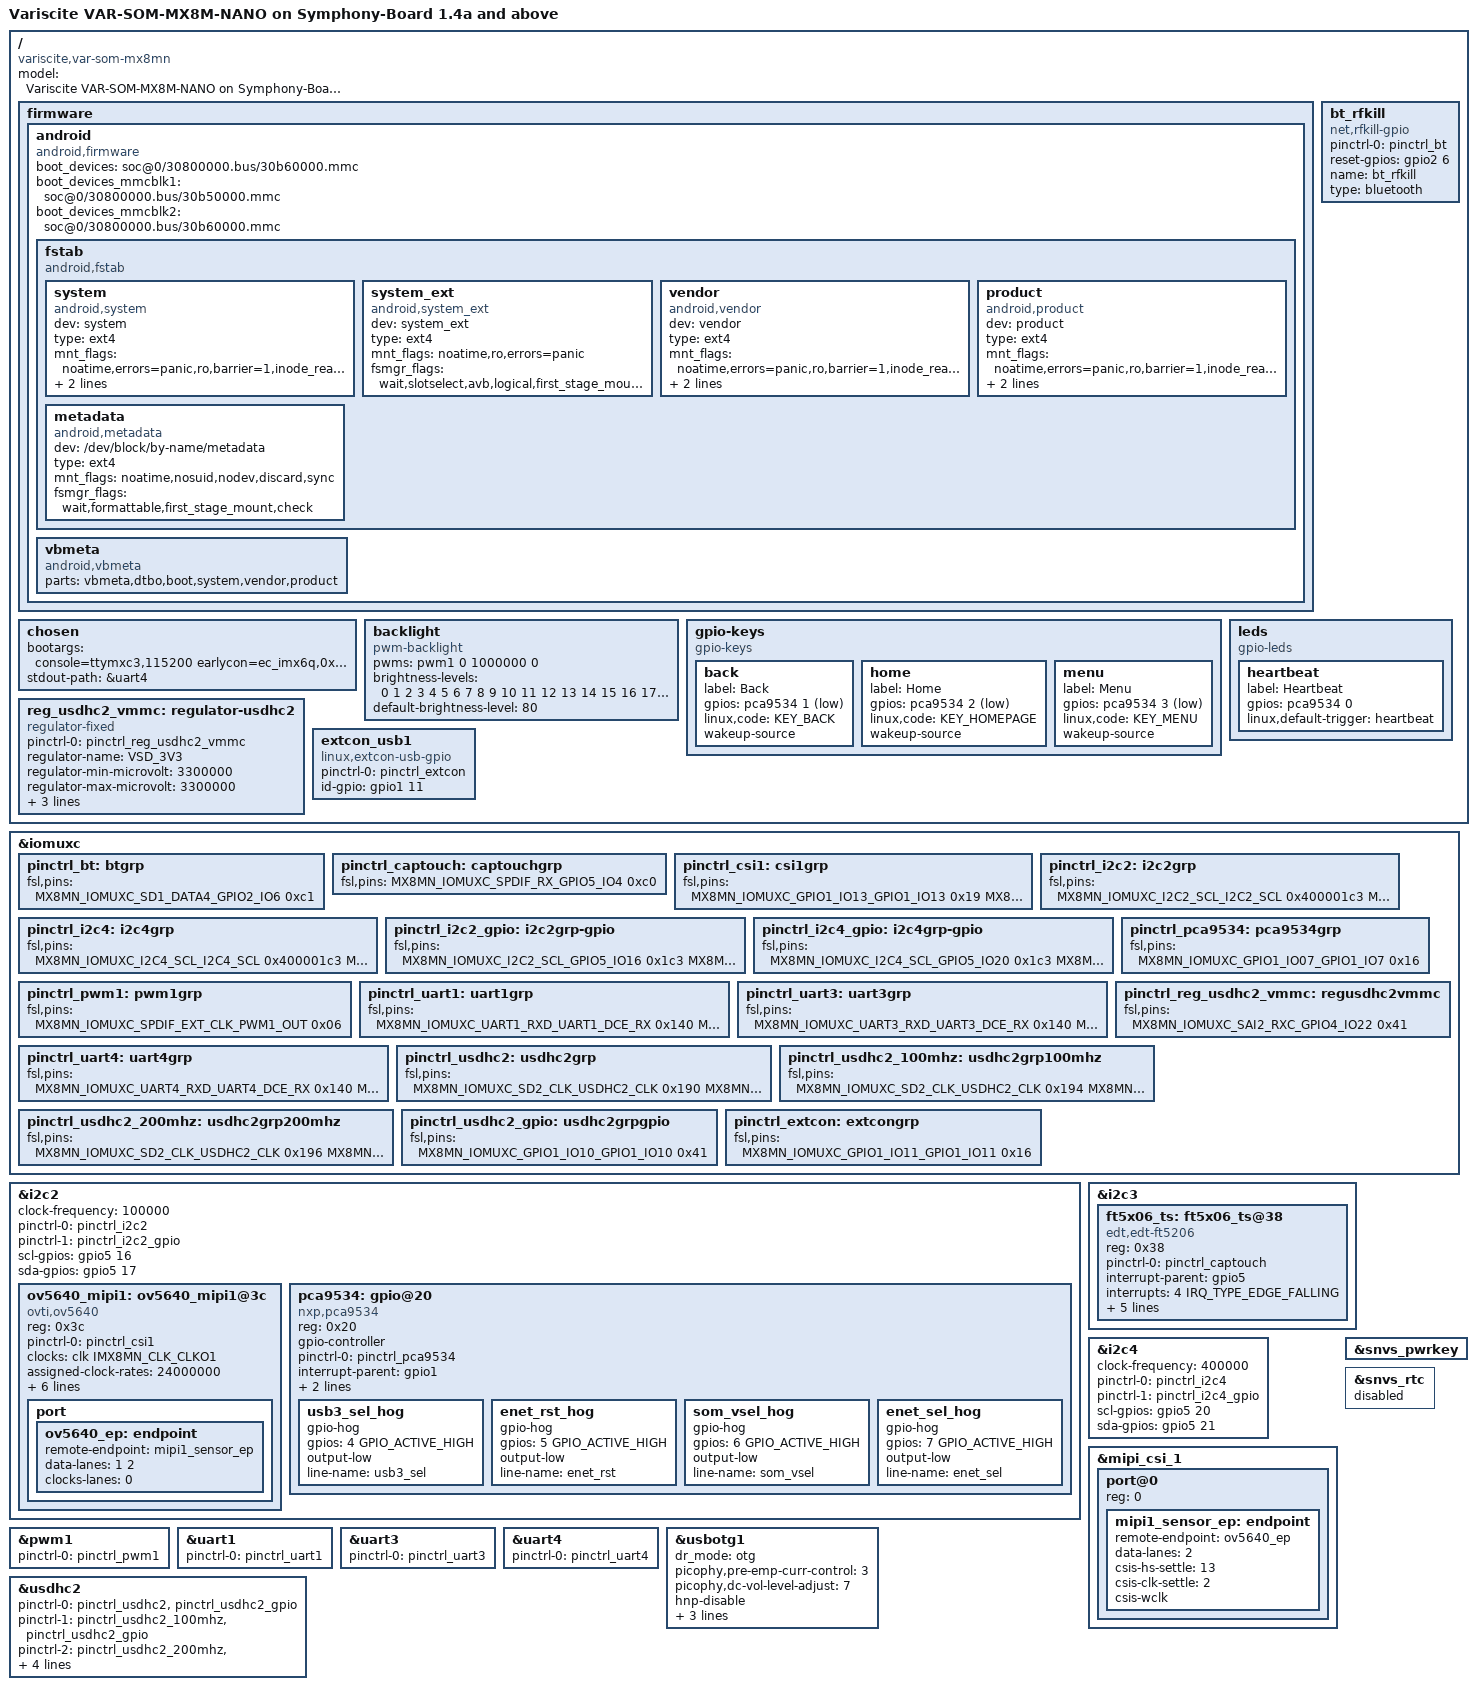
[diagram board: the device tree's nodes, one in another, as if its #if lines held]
// SPDX-License-Identifier: (GPL-2.0+ OR MIT)
/*
 * Copyright 2019 NXP
 * Copyright 2019-2020 Variscite Ltd.
 */

/dts-v1/;

#include <dt-bindings/usb/pd.h>
#include "imx8mn-var-som.dtsi"

/ {
	firmware {
		android {
			compatible = "android,firmware";
			/* default emmc node used for GSI */
			boot_devices = "soc@0/30800000.bus/30b60000.mmc";
			/* sd card node which used if androidboot.boot_device_root=mmcblk1 */
			boot_devices_mmcblk1 = "soc@0/30800000.bus/30b50000.mmc";
			/* emmc node which used if androidboot.boot_device_root=mmcblk2 */
			boot_devices_mmcblk2 = "soc@0/30800000.bus/30b60000.mmc";
			fstab {
				compatible = "android,fstab";
				system {
					compatible = "android,system";
					dev = "system";
					type = "ext4";
					mnt_flags = "noatime,errors=panic,ro,barrier=1,inode_readahead_blks=8";
					fsmgr_flags = "wait,slotselect,avb,avb_keys=/avb,logical,first_stage_mount";
				};
				system_ext {
					compatible = "android,system_ext";
					dev = "system_ext";
					type = "ext4";
					mnt_flags = "noatime,ro,errors=panic";
					fsmgr_flags = "wait,slotselect,avb,logical,first_stage_mount";
				};
				vendor {
					compatible = "android,vendor";
					dev = "vendor";
					type = "ext4";
					mnt_flags = "noatime,errors=panic,ro,barrier=1,inode_readahead_blks=8";
					fsmgr_flags = "wait,slotselect,avb,logical,first_stage_mount";
				};
				product {
					compatible = "android,product";
					dev = "product";
					type = "ext4";
					mnt_flags = "noatime,errors=panic,ro,barrier=1,inode_readahead_blks=8";
					fsmgr_flags = "wait,slotselect,avb,logical,first_stage_mount";
				};
				metadata {
					compatible = "android,metadata";
					dev = "/dev/block/by-name/metadata";
					type = "ext4";
					mnt_flags = "noatime,nosuid,nodev,discard,sync";
					fsmgr_flags = "wait,formattable,first_stage_mount,check";
				};
			};
			vbmeta {
				/*we need use FirstStageMountVBootV2 if we enable avb*/
				compatible = "android,vbmeta";
				/*parts means the partition witch can be mount in first stage*/
				parts = "vbmeta,dtbo,boot,system,vendor,product";
			};
		};
	};
};

/ {
	 bt_rfkill {
               compatible = "net,rfkill-gpio";
               pinctrl-names = "default";
               pinctrl-0 = <&pinctrl_bt>;
               reset-gpios = <&gpio2 6 GPIO_ACTIVE_HIGH>;
               name = "bt_rfkill";
               type = "bluetooth";
               status = "okay";
       };
};

/ {
	model = "Variscite VAR-SOM-MX8M-NANO on Symphony-Board 1.4a and above";
	compatible = "variscite,var-som-mx8mn", "fsl,imx8mn";

	chosen {
		bootargs = "console=ttymxc3,115200 earlycon=ec_imx6q,0x30a60000,115200 loglevel=8";
		stdout-path = &uart4;
	};

	backlight: backlight {
		compatible = "pwm-backlight";
		pwms = <&pwm1 0 1000000 0>;
		brightness-levels = < 0  1  2  3  4  5  6  7  8  9
				     10 11 12 13 14 15 16 17 18 19
				     20 21 22 23 24 25 26 27 28 29
				     30 31 32 33 34 35 36 37 38 39
				     40 41 42 43 44 45 46 47 48 49
				     50 51 52 53 54 55 56 57 58 59
				     60 61 62 63 64 65 66 67 68 69
				     70 71 72 73 74 75 76 77 78 79
				     80 81 82 83 84 85 86 87 88 89
				     90 91 92 93 94 95 96 97 98 99
				    100>;
		default-brightness-level = <80>;
		status = "okay";
	};

	gpio-keys {
		compatible = "gpio-keys";
		status = "okay";

		back {
			label = "Back";
			gpios = <&pca9534 1 GPIO_ACTIVE_LOW>;
			linux,code = <KEY_BACK>;
			wakeup-source;
		};

		home {
			label = "Home";
			gpios = <&pca9534 2 GPIO_ACTIVE_LOW>;
			linux,code = <KEY_HOMEPAGE>;
			wakeup-source;
		};

		menu {
			label = "Menu";
			gpios = <&pca9534 3 GPIO_ACTIVE_LOW>;
			linux,code = <KEY_MENU>;
			wakeup-source;
		};
	};

	leds {
		compatible = "gpio-leds";
		status = "okay";

		heartbeat {
			label = "Heartbeat";
			gpios = <&pca9534 0 GPIO_ACTIVE_HIGH>;
			linux,default-trigger = "heartbeat";
		};
	};

	reg_usdhc2_vmmc: regulator-usdhc2 {
		compatible = "regulator-fixed";
		pinctrl-names = "default";
		pinctrl-0 = <&pinctrl_reg_usdhc2_vmmc>;
		regulator-name = "VSD_3V3";
		regulator-min-microvolt = <3300000>;
		regulator-max-microvolt = <3300000>;
		gpio = <&gpio4 22 GPIO_ACTIVE_HIGH>;
		off-on-delay = <20000>;
		enable-active-high;
	};

	extcon_usb1: extcon_usb1 {
		compatible = "linux,extcon-usb-gpio";
		pinctrl-names = "default";
		pinctrl-0 = <&pinctrl_extcon>;
		id-gpio = <&gpio1 11 GPIO_ACTIVE_HIGH>;
		status = "okay";
	};
};

&iomuxc {

	pinctrl_bt: btgrp {
		fsl,pins = <
			MX8MN_IOMUXC_SD1_DATA4_GPIO2_IO6               0xc1 /* BT_REG_ON    */
		>;
        };

	pinctrl_captouch: captouchgrp {
		fsl,pins = <
			MX8MN_IOMUXC_SPDIF_RX_GPIO5_IO4			0xc0
		>;
	};

	pinctrl_csi1: csi1grp {
		fsl,pins = <
			MX8MN_IOMUXC_GPIO1_IO13_GPIO1_IO13		0x19
			MX8MN_IOMUXC_ECSPI2_MISO_GPIO5_IO12		0x19
		>;
	};

	pinctrl_i2c2: i2c2grp {
		fsl,pins = <
			MX8MN_IOMUXC_I2C2_SCL_I2C2_SCL			0x400001c3
			MX8MN_IOMUXC_I2C2_SDA_I2C2_SDA			0x400001c3
		>;
	};

	pinctrl_i2c4: i2c4grp {
		fsl,pins = <
			MX8MN_IOMUXC_I2C4_SCL_I2C4_SCL			0x400001c3
			MX8MN_IOMUXC_I2C4_SDA_I2C4_SDA			0x400001c3
		>;
	};

	pinctrl_i2c2_gpio: i2c2grp-gpio {
		fsl,pins = <
			MX8MN_IOMUXC_I2C2_SCL_GPIO5_IO16		0x1c3
			MX8MN_IOMUXC_I2C2_SDA_GPIO5_IO17		0x1c3
		>;
	};

	pinctrl_i2c4_gpio: i2c4grp-gpio {
		fsl,pins = <
			MX8MN_IOMUXC_I2C4_SCL_GPIO5_IO20		0x1c3
			MX8MN_IOMUXC_I2C4_SDA_GPIO5_IO21		0x1c3
		>;
	};

	pinctrl_pca9534: pca9534grp {
		fsl,pins = <
			MX8MN_IOMUXC_GPIO1_IO07_GPIO1_IO7		0x16
		>;
	};

	pinctrl_pwm1: pwm1grp {
		fsl,pins = <
			MX8MN_IOMUXC_SPDIF_EXT_CLK_PWM1_OUT		0x06
		>;
	};

	pinctrl_uart1: uart1grp {
		fsl,pins = <
			MX8MN_IOMUXC_UART1_RXD_UART1_DCE_RX		0x140
			MX8MN_IOMUXC_UART1_TXD_UART1_DCE_TX		0x140
		>;
	};

	pinctrl_uart3: uart3grp {
		fsl,pins = <
			MX8MN_IOMUXC_UART3_RXD_UART3_DCE_RX		0x140
			MX8MN_IOMUXC_UART3_TXD_UART3_DCE_TX		0x140
		>;
	};

	pinctrl_uart4: uart4grp {
		fsl,pins = <
			MX8MN_IOMUXC_UART4_RXD_UART4_DCE_RX		0x140
			MX8MN_IOMUXC_UART4_TXD_UART4_DCE_TX		0x140
		>;
	};

	pinctrl_reg_usdhc2_vmmc: regusdhc2vmmc {
		fsl,pins = <
			MX8MN_IOMUXC_SAI2_RXC_GPIO4_IO22		0x41
		>;
	};

	pinctrl_usdhc2: usdhc2grp {
		fsl,pins = <
			MX8MN_IOMUXC_SD2_CLK_USDHC2_CLK			0x190
			MX8MN_IOMUXC_SD2_CMD_USDHC2_CMD			0x1d0
			MX8MN_IOMUXC_SD2_DATA0_USDHC2_DATA0		0x1d0
			MX8MN_IOMUXC_SD2_DATA1_USDHC2_DATA1		0x1d0
			MX8MN_IOMUXC_SD2_DATA2_USDHC2_DATA2		0x1d0
			MX8MN_IOMUXC_SD2_DATA3_USDHC2_DATA3		0x1d0
			MX8MN_IOMUXC_GPIO1_IO04_USDHC2_VSELECT		0x1d0
		>;
	};

	pinctrl_usdhc2_100mhz: usdhc2grp100mhz {
		fsl,pins = <
			MX8MN_IOMUXC_SD2_CLK_USDHC2_CLK			0x194
			MX8MN_IOMUXC_SD2_CMD_USDHC2_CMD			0x1d4
			MX8MN_IOMUXC_SD2_DATA0_USDHC2_DATA0		0x1d4
			MX8MN_IOMUXC_SD2_DATA1_USDHC2_DATA1		0x1d4
			MX8MN_IOMUXC_SD2_DATA2_USDHC2_DATA2		0x1d4
			MX8MN_IOMUXC_SD2_DATA3_USDHC2_DATA3		0x1d4
			MX8MN_IOMUXC_GPIO1_IO04_USDHC2_VSELECT		0x1d0
		>;
	};

	pinctrl_usdhc2_200mhz: usdhc2grp200mhz {
		fsl,pins = <
			MX8MN_IOMUXC_SD2_CLK_USDHC2_CLK			0x196
			MX8MN_IOMUXC_SD2_CMD_USDHC2_CMD			0x1d6
			MX8MN_IOMUXC_SD2_DATA0_USDHC2_DATA0		0x1d6
			MX8MN_IOMUXC_SD2_DATA1_USDHC2_DATA1		0x1d6
			MX8MN_IOMUXC_SD2_DATA2_USDHC2_DATA2		0x1d6
			MX8MN_IOMUXC_SD2_DATA3_USDHC2_DATA3		0x1d6
			MX8MN_IOMUXC_GPIO1_IO04_USDHC2_VSELECT		0x1d0
		>;
	};

	pinctrl_usdhc2_gpio: usdhc2grpgpio {
		fsl,pins = <
			MX8MN_IOMUXC_GPIO1_IO10_GPIO1_IO10		0x41
		>;
	};

	pinctrl_extcon: extcongrp {
		fsl,pins = <
			MX8MN_IOMUXC_GPIO1_IO11_GPIO1_IO11		0x16
		>;
	};
};

&i2c2 {
	clock-frequency = <100000>;
	pinctrl-names = "default", "gpio";
	pinctrl-0 = <&pinctrl_i2c2>;
	pinctrl-1 = <&pinctrl_i2c2_gpio>;
	scl-gpios = <&gpio5 16 GPIO_ACTIVE_HIGH>;
	sda-gpios = <&gpio5 17 GPIO_ACTIVE_HIGH>;
	status = "okay";

	ov5640_mipi1: ov5640_mipi1@3c {
		status = "okay";
		compatible = "ovti,ov5640";
		reg = <0x3c>;
		pinctrl-names = "default";
		pinctrl-0 = <&pinctrl_csi1>;
		clocks = <&clk IMX8MN_CLK_CLKO1>;
		clock-names = "xclk";
/* Disabled CLKO1, since VAR-SOM-MX8M-NANO camera expansion board uses
 * its own oscillator. Enable CLK01 if your design requires it
 */
#if 0
		assigned-clocks = <&clk IMX8MN_CLK_CLKO1>;
		assigned-clock-parents = <&clk IMX8MN_CLK_24M>;
#endif
		assigned-clock-rates = <24000000>;
		csi_id = <0>;
		powerdown-gpios = <&gpio5 12 GPIO_ACTIVE_HIGH>;
		reset-gpios = <&gpio1 13 GPIO_ACTIVE_LOW>;
		mclk = <24000000>;
		mclk_source = <0>;
		mipi_csi;
		port {
			ov5640_ep: endpoint {
				remote-endpoint = <&mipi1_sensor_ep>;
				data-lanes = <1 2>;
				clocks-lanes = <0>;
			};
		};
	};

	/* GPIO expander */
	pca9534: gpio@20 {
		status = "okay";
		compatible = "nxp,pca9534";
		reg = <0x20>;
		gpio-controller;
		pinctrl-names = "default";
		pinctrl-0 = <&pinctrl_pca9534>;
		interrupt-parent = <&gpio1>;
		interrupts = <7 IRQ_TYPE_EDGE_FALLING>;
		#gpio-cells = <2>;
		wakeup-source;

		usb3_sel_hog {
			gpio-hog;
			gpios = <4 GPIO_ACTIVE_HIGH>;
			output-low;
			line-name = "usb3_sel";
		};

		enet_rst_hog {
			gpio-hog;
			gpios = <5 GPIO_ACTIVE_HIGH>;
			output-low;
			line-name = "enet_rst";
		};

		som_vsel_hog {
			gpio-hog;
			gpios = <6 GPIO_ACTIVE_HIGH>;
			output-low;
			line-name = "som_vsel";
		};

		enet_sel_hog {
			gpio-hog;
			gpios = <7 GPIO_ACTIVE_HIGH>;
			output-low;
			line-name = "enet_sel";
		};
	};
};

&i2c3 {
	/* Capacitive touch controller */
#ifdef DEV_KIT
	ft5x06_ts: ft5x06_ts@38 {
		status = "okay";
		compatible = "edt,edt-ft5206";
		reg = <0x38>;
		pinctrl-names = "default";
		pinctrl-0 = <&pinctrl_captouch>;
		interrupt-parent = <&gpio5>;
		interrupts = <4 IRQ_TYPE_EDGE_FALLING>;
		touchscreen-size-x = <800>;
		touchscreen-size-y = <480>;
		touchscreen-inverted-x;
		touchscreen-inverted-y;
		wakeup-source;
	};
#else
	gt928@5d {
		status = "okay";
		compatible = "goodix,gt928";
		reg = <0x5d>; // 7 low bit only => 0101 1101 => 1011 101[0] => 0xBA
		pinctrl-names = "default";
		pinctrl-0 = <&pinctrl_captouch>;
		interrupt-parent = <&gpio5>;
		interrupts = <4 0>;
		irq-gpios = <&gpio5 4 0>;
		reset-gpios = <&gpio4 27 0>;
		touchscreen-size-x = <1920>; //horizontal resolution of touchscreen(in pixels)
		touchscreen-size-y = <1280>; //vertical resolution of touchscreen(in pixels)
		/*touchscreen-inverted-x;*/
		/*touchscreen-inverted-y;*/
		goodix,cfg-group0 = [
			43 80 07 00 05 0A 3D 00 01 08 28
			0F 5A 37 03 05 00 00 00 00 00 00
			00 18 1A 1E 14 90 30 CC 6E 69 31
			0D 00 00 00 01 03 1D 00 00 00 00
			00 03 00 00 00 00 00 14 32 94 D5
			02 07 00 00 04 93 29 00 89 2E 00
			80 34 00 78 3A 00 70 42 00 70 00
			00 00 00 00 00 00 00 00 00 00 00
			00 00 00 00 00 00 00 00 00 00 00
			00 00 00 00 00 00 00 00 00 00 00
			00 00 00 01 04 05 06 07 08 09 0C
			0D 0E 0F 10 11 14 15 16 17 18 19
			1A 1B 1C 1D 00 00 00 00 00 00 00
			02 04 06 07 08 0A 0C 0D 0E 0F 10
			11 12 13 14 19 1B 1C 1E 1F 20 21
			22 23 24 25 26 27 28 29 2A 00 00
			00 00 00 00 00 00 00 00 E4 01
			];

			// 42 80 07 00 05 0A 3D 00 01 08 28
			// 0F 50 32 03 05 00 00 00 00 00 00
			// 00 18 1A 1E 14 90 30 CC 34 36 82
			// 0A 00 00 00 01 03 1D 00 00 00 00
			// 00 03 00 00 00 00 00 27 46 94 D5
			// 02 07 00 00 04 93 29 00 89 2E 00
			// 80 34 00 78 3A 00 70 42 00 70 00
			// 00 00 00 00 00 00 00 00 00 00 00
			// 00 00 00 00 00 00 00 00 00 00 00
			// 00 00 00 00 00 00 00 00 00 00 00
			// 00 00 00 01 04 05 06 07 08 09 0C
			// 0D 0E 0F 10 11 14 15 16 17 18 19
			// 1A 1B 1C 1D 00 00 00 00 00 00 00
			// 02 04 06 07 08 0A 0C 0D 0E 0F 10
			// 11 12 13 14 19 1B 1C 1E 1F 20 21
			// 22 23 24 25 26 27 28 29 2A 00 00
			// 00 00 00 00 00 00 00 00 EC 01

			// // original 7' TFT
			// 42 D0 02 00 05 05 75 01 01 0F 24 
			// 0F 64 3C 03 05 00 00 00 02 00 00 
			// 00 16 19 1C 14 8C 0E 0E 24 00 31 
			// 0D 00 00 00 83 33 1D 00 41 00 00 
			// 00 00 00 08 0A 00 2B 1C 3C 94 D5 
			// 03 08 00 00 04 93 1E 00 82 23 00 
			// 74 29 00 69 2F 00 5F 37 00 5F 20 
			// 40 60 00 F0 40 30 55 50 27 00 00 
			// 00 00 00 00 00 00 00 00 00 00 00 
			// 00 00 00 00 00 00 00 14 19 00 00 
			// 50 50 02 04 06 08 0A 0C 0E 10 12 
			// 14 16 18 1A 1C 00 00 00 00 00 00 
			// 00 00 00 00 00 00 00 00 00 00 1D 
			// 1E 1F 20 21 22 24 26 28 29 2A 1C 
			// 18 16 14 13 12 10 0F 0C 0A 08 06 
			// 04 02 00 00 00 00 00 00 00 00 00 
			// 00 00 00 00 00 00 00 00 9C 01
						
	};
#endif

	/* DS1337 RTC module */
	// rtc@68 {
	// 	status = "disabled";
	// 	compatible = "dallas,ds1337";
	// 	reg = <0x68>;
	// };
};

&i2c4 {
	clock-frequency = <400000>;
	pinctrl-names = "default", "gpio";
	pinctrl-0 = <&pinctrl_i2c4>;
	pinctrl-1 = <&pinctrl_i2c4_gpio>;
	scl-gpios = <&gpio5 20 GPIO_ACTIVE_HIGH>;
	sda-gpios = <&gpio5 21 GPIO_ACTIVE_HIGH>;
	status = "okay";
};

&mipi_csi_1 {
	#address-cells = <1>;
	#size-cells = <0>;
	status = "okay";
	port@0 {
		reg = <0>;
		mipi1_sensor_ep: endpoint {
			remote-endpoint = <&ov5640_ep>;
			data-lanes = <2>;
			csis-hs-settle = <13>;
			csis-clk-settle = <2>;
			csis-wclk;
		};
	};
};

&pwm1 {
	status = "okay";
	pinctrl-names = "default";
	pinctrl-0 = <&pinctrl_pwm1>;
};

&snvs_pwrkey {
	status = "okay";
};

&snvs_rtc {
	status = "disabled";
};

/* Header */
&uart1 {
	pinctrl-names = "default";
	pinctrl-0 = <&pinctrl_uart1>;
	status = "okay";
};

/* Header */
&uart3 {
	pinctrl-names = "default";
	pinctrl-0 = <&pinctrl_uart3>;
	status = "okay";
};

/* Console */
&uart4 {
	pinctrl-names = "default";
	pinctrl-0 = <&pinctrl_uart4>;
	status = "okay";
	/delete-property/ dmas;
	/delete-property/ dma-names;
};

&usbotg1 {
	dr_mode = "otg";
	picophy,pre-emp-curr-control = <3>;
	picophy,dc-vol-level-adjust = <7>;
	hnp-disable;
	srp-disable;
	adp-disable;
	extcon = <0>, <&extcon_usb1>;
	status = "okay";
};

/* SD */
&usdhc2 {
	pinctrl-names = "default", "state_100mhz", "state_200mhz";
	pinctrl-0 = <&pinctrl_usdhc2>, <&pinctrl_usdhc2_gpio>;
	pinctrl-1 = <&pinctrl_usdhc2_100mhz>, <&pinctrl_usdhc2_gpio>;
	pinctrl-2 = <&pinctrl_usdhc2_200mhz>, <&pinctrl_usdhc2_gpio>;
	cd-gpios = <&gpio1 10 GPIO_ACTIVE_LOW>;
	bus-width = <4>;
	vmmc-supply = <&reg_usdhc2_vmmc>;
	status = "okay";
};
